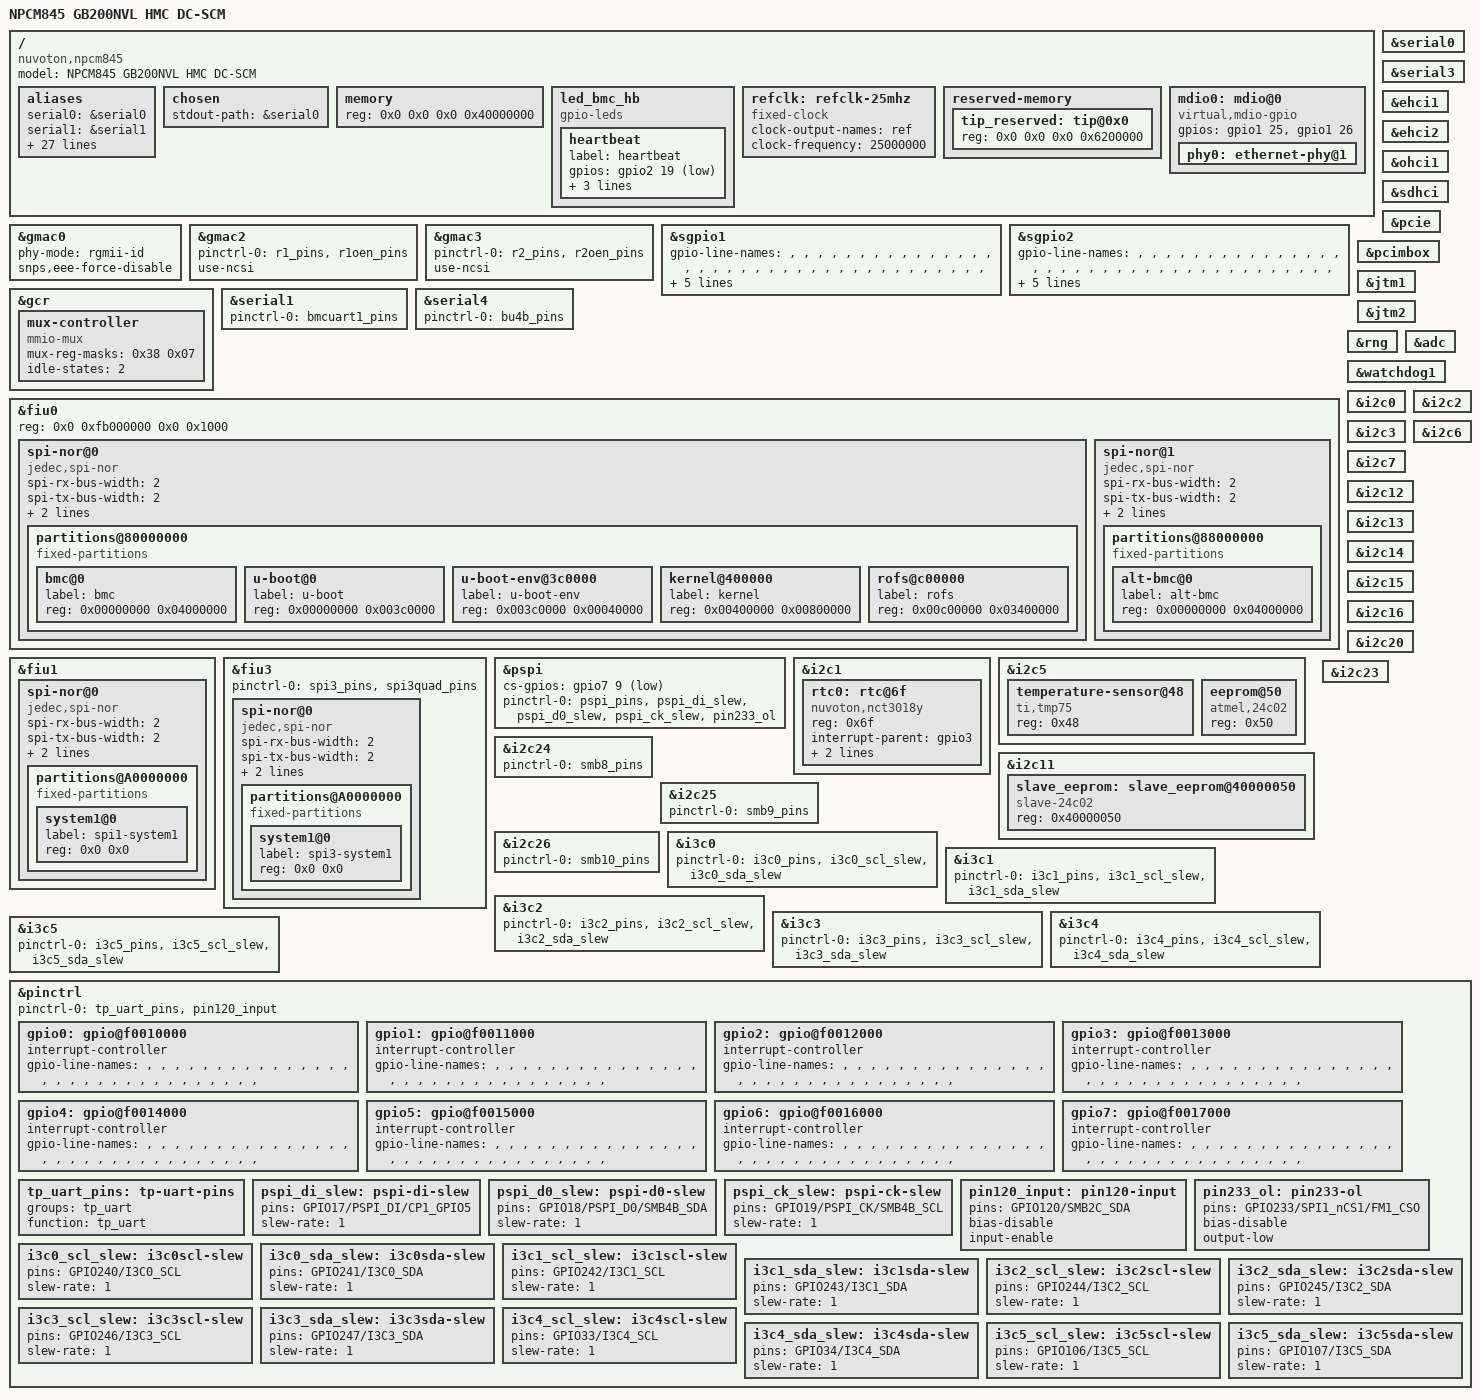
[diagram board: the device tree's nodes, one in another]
// SPDX-License-Identifier: GPL-2.0
// Copyright (c) 2025 Nuvoton Technology

/dts-v1/;
#include "nuvoton-npcm845.dtsi"
#include <dt-bindings/leds/common.h>

/ {
	model = "NPCM845 GB200NVL HMC DC-SCM";
	compatible = "nuvoton,npcm845";

	aliases {
		serial0 = &serial0;
		serial1 = &serial1;
		serial2 = &serial3;
		serial3 = &serial4;
		ethernet0 = &gmac0;
		ethernet2 = &gmac2;
		ethernet3 = &gmac3;
		mdio-gpio0 = &mdio0;
		fiu0 = &fiu0;
		fiu1 = &fiu1;
		fiu3 = &fiu3;
		i2c0 = &i2c0;
		i2c1 = &i2c1;
		i2c2 = &i2c2;
		i2c3 = &i2c3;
		i2c5 = &i2c5;
		i2c6 = &i2c6;
		i2c7 = &i2c7;
		i2c11 = &i2c11;
		i2c12 = &i2c12;
		i2c13 = &i2c13;
		i2c14 = &i2c14;
		i2c15 = &i2c15;
		i2c16 = &i2c16;
		i2c20 = &i2c20;
		i2c23 = &i2c23;
		i2c24 = &i2c24;
		i2c25 = &i2c25;
		i2c26 = &i2c26;
	};

	chosen {
		stdout-path = &serial0;
	};

	memory {
		reg = <0x0 0x0 0x0 0x40000000>;
	};

	led_bmc_hb {
		compatible = "gpio-leds";
		heartbeat {
			label = "heartbeat";
			gpios = <&gpio2 19 GPIO_ACTIVE_LOW>; /* gpio83 */
			linux,default-trigger = "timer";
			led-pattern = <1000 1000>;
			default-state = "on";
		};
	};

	refclk: refclk-25mhz {
		compatible = "fixed-clock";
		clock-output-names = "ref";
		clock-frequency = <25000000>;
		#clock-cells = <0>;
	};

	reserved-memory {
		#address-cells = <2>;
		#size-cells = <2>;
		ranges;

		tip_reserved: tip@0x0 {
			reg = <0x0 0x0 0x0 0x6200000>;
		};
	};

	mdio0: mdio@0 {
		compatible = "virtual,mdio-gpio";
		gpios = <&gpio1 25 GPIO_ACTIVE_HIGH>,
			<&gpio1 26 GPIO_ACTIVE_HIGH>; 
		#address-cells = <1>;
		#size-cells = <0>;

		phy0: ethernet-phy@1 {
		};
	};
};

&gmac0 {
	phy-mode = "rgmii-id";
	snps,eee-force-disable;
	status = "okay";
};

&gmac2 {
	//status = "okay";
	pinctrl-names = "default";
	pinctrl-0 = <&r1_pins
		     &r1oen_pins>;
	use-ncsi;
	//mellanox,multi-host;
};

&gmac3 {
	//status = "okay";
	pinctrl-names = "default";
	pinctrl-0 = <&r2_pins
		     &r2oen_pins>;
	use-ncsi;
	//mellanox,multi-host;
};

&sgpio1 {
	status = "okay";
	gpio-line-names =
		"","","","","","","","",
		"","","","","","","","",
		"","","","","","","","",
		"","","","","","","","",
		"","","","","","","","",
		"","","","","","","","",
		"","","","","","","","",
		"","","","","","","","",
		"","","","","","","","",
		"","","","","","","","",
		"","","","","","","","",
		"","","","","","","","",
		"","","","","","","","",
		"","","","","","","","",
		"","","","","","","","",
		"","","","","","","","";
};

&sgpio2 {
	status = "okay";
	gpio-line-names =
		"","","","","","","","",
		"","","","","","","","",
		"","","","","","","","",
		"","","","","","","","",
		"","","","","","","","",
		"","","","","","","","",
		"","","","","","","","",
		"","","","","","","","",
		"","","","","","","","",
		"","","","","","","","",
		"","","","","","","","",
		"","","","","","","","",
		"","","","","","","","",
		"","","","","","","","",
		"","","","","","","","",
		"","","","","","","","";
};

&gcr {
	mux-controller {
		compatible = "mmio-mux";
		#mux-control-cells = <1>;
		mux-reg-masks = <0x38 0x07>;
		idle-states = <2>; // UART switch mode 3
	};
};

&serial0 {
	status = "okay";
};

&serial1 {
	status = "okay";
	pinctrl-names = "default";
	pinctrl-0 = <&bmcuart1_pins>;
};

&serial3 {
	status = "okay";
};

&serial4 {
	status = "okay";
	pinctrl-names = "default";
	pinctrl-0 = <&bu4b_pins>;
};

&fiu0 {
	status = "okay";
	reg = <0x0 0xfb000000 0x0 0x1000>;
	reg-names = "control";
	spi-nor@0 {
		compatible = "jedec,spi-nor";
		#address-cells = <1>;
		#size-cells = <1>;
		spi-rx-bus-width = <2>;
		spi-tx-bus-width = <2>;
		reg = <0>;
		spi-max-frequency = <5000000>;
		partitions@80000000 {
			compatible = "fixed-partitions";
			#address-cells = <1>;
			#size-cells = <1>;
			bmc@0 {
				label = "bmc";
				reg = <0x00000000 0x04000000>;
			};
			u-boot@0 {
				label = "u-boot";
				reg = <0x00000000 0x003c0000>;
			};
			u-boot-env@3c0000 {
				label = "u-boot-env";
				reg = <0x003c0000 0x00040000>;
			};
			kernel@400000 {
				label = "kernel";
				reg = <0x00400000 0x00800000>;
			};
			rofs@c00000 {
				label = "rofs";
				reg = <0x00c00000 0x03400000>;
			};
		};
	};
	spi-nor@1 {
		compatible = "jedec,spi-nor";
		#address-cells = <1>;
		#size-cells = <1>;
		spi-rx-bus-width = <2>;
		spi-tx-bus-width = <2>;
		reg = <1>;
		spi-max-frequency = <5000000>;
		partitions@88000000 {
			compatible = "fixed-partitions";
			#address-cells = <1>;
			#size-cells = <1>;
			alt-bmc@0 {
				label = "alt-bmc";
				reg = <0x00000000 0x04000000>;
			};
		};
	};
};

&fiu1 {
	/*pinctrl-0 = <&spi1_pins>, <&spi1quad_pins>;*/
	status = "okay";
	spi-nor@0 {
		compatible = "jedec,spi-nor";
		#address-cells = <1>;
		#size-cells = <1>;
		spi-rx-bus-width = <2>;
		spi-tx-bus-width = <2>;
		reg = <0>;
		spi-max-frequency = <5000000>;
		partitions@A0000000 {
			compatible = "fixed-partitions";
			#address-cells = <1>;
			#size-cells = <1>;
			system1@0 {
				label = "spi1-system1";
				reg = <0x0 0x0>;
			};
		};
	};
};

&fiu3 {
	pinctrl-0 = <&spi3_pins>, <&spi3quad_pins>;
	status = "okay";
	spi-nor@0 {
		compatible = "jedec,spi-nor";
		#address-cells = <1>;
		#size-cells = <1>;
		spi-rx-bus-width = <2>;
		spi-tx-bus-width = <2>;
		reg = <0>;
		spi-max-frequency = <5000000>;
		partitions@A0000000 {
			compatible = "fixed-partitions";
			#address-cells = <1>;
			#size-cells = <1>;
			system1@0 {
				label = "spi3-system1";
				reg = <0x0 0x0>;
			};
		};
	};
};

&ehci1 {
	status = "okay";
};

&ehci2 {
	status = "okay";
};

&ohci1 {
        status = "okay";
};

&sdhci {
	status = "okay";
};

&pcie {
	/* used for e1000e PCI -> AXI window opening */
	//dma-ranges = <0x02000000 0 0x00000000 0x0 0x00000000 0 0x40000000>;
	//npcm-pci-ep-rst = <&gpio3 24 1>;
	status = "okay";
};

&pcimbox {
	status = "okay";
};

&jtm1 {
	status = "okay";
};

&jtm2 {
	status = "okay";
};

&rng {
	status = "okay";
};

&adc {
	#io-channel-cells = <1>;
	status = "okay";
};

&watchdog1 {
	status = "okay";
};


&pspi {
	status = "okay";
	cs-gpios = <&gpio7 9 GPIO_ACTIVE_LOW>; /* gpio233 */
	pinctrl-0 = <&pspi_pins
		     &pspi_di_slew
		     &pspi_d0_slew
		     &pspi_ck_slew
		     &pin233_ol>;

	// NPCT760AACYX TPM
};

&i2c0 {
	status = "okay";
};

&i2c1 {
	status = "okay";
	rtc0: rtc@6f {
		compatible = "nuvoton,nct3018y";
		reg = <0x6f>;
		interrupt-parent = <&gpio3>;
		interrupts = <24 IRQ_TYPE_EDGE_FALLING>; /* gpio120 */
		interrupt-names = "irq";
		wakeup-source;
	};
};

&i2c2 {
	status = "okay";
};

&i2c3 {
	status = "okay";
};

&i2c5 {
	status = "okay";
	temperature-sensor@48 {
		compatible = "ti,tmp75";
		reg = <0x48>;
	};

	eeprom@50 {
		compatible = "atmel,24c02";
		reg = <0x50>;
	};
};

&i2c6 {
	status = "okay";
};

&i2c7 {
	status = "okay";
};

&i2c11 {
	status = "okay";
	//Internal eeprom for DVO
	slave_eeprom: slave_eeprom@40000050 {
		compatible = "slave-24c02";
		reg = <0x40000050>;
		status = "okay";
	};
};

&i2c12 {
	status = "okay";
};

&i2c13 {
	status = "okay";
};

&i2c14 {
	status = "okay";
};

&i2c15 {
	status = "okay";
};

&i2c16 {
	status = "okay";
};

&i2c20 {
	status = "okay";
};

&i2c23 {
	status = "okay";
};

&i2c24 {
	status = "okay";
	pinctrl-0 = <&smb8_pins>;
};

&i2c25 {
	status = "okay";
	pinctrl-0 = <&smb9_pins>;
};

&i2c26 {
	status = "okay";
	pinctrl-0 = <&smb10_pins>;
};

&i3c0 {
	status = "okay";
	pinctrl-names = "default";
	pinctrl-0 = <&i3c0_pins
		     &i3c0_scl_slew
		     &i3c0_sda_slew>;
};

&i3c1 {
	status = "okay";
	pinctrl-names = "default";
	pinctrl-0 = <&i3c1_pins
		     &i3c1_scl_slew
		     &i3c1_sda_slew>;
};

&i3c2 {
	status = "okay";
	pinctrl-names = "default";
	pinctrl-0 = <&i3c2_pins
		     &i3c2_scl_slew
		     &i3c2_sda_slew>;
};

&i3c3 {
	status = "okay";
	pinctrl-names = "default";
	pinctrl-0 = <&i3c3_pins
		     &i3c3_scl_slew
		     &i3c3_sda_slew>;
};

&i3c4 {
	status = "okay";
	pinctrl-names = "default";
	pinctrl-0 = <&i3c4_pins
		     &i3c4_scl_slew
		     &i3c4_sda_slew>;
};

&i3c5 {
	status = "okay";
	pinctrl-names = "default";
	pinctrl-0 = <&i3c5_pins
		     &i3c5_scl_slew
		     &i3c5_sda_slew>;
};

&pinctrl {
	pinctrl-names = "default";
	pinctrl-0 = <&tp_uart_pins
		     &pin120_input>;

	gpio0: gpio@f0010000 {
		interrupt-controller;
		#interrupt-cells = <2>;
		gpio-line-names =
		/*0-31*/
		"","","","","","","","",
		"","","","","","","","",
		"","","","","","","","",
		"","","","","","","","";
	};

	gpio1: gpio@f0011000 {
		interrupt-controller;
		#interrupt-cells = <2>;
		gpio-line-names =
		/*32-63*/
		"","","","","","","","",
		"","","","","","","","",
		"","","","","","","","",
		"","","","","","","","";
	};

	gpio2: gpio@f0012000 {
		interrupt-controller;
		#interrupt-cells = <2>;
		gpio-line-names =
		/*64-95*/
		"","","","","","","","",
		"","","","","","","","",
		"","","","","","","","",
		"","","","","","","","";
	};

	gpio3: gpio@f0013000 {
		interrupt-controller;
		#interrupt-cells = <2>; gpio-line-names =
		/*96-127*/
		"","","","","","","","",
		"","","","","","","","",
		"","","","","","","","",
		"","","","","","","","";
	};

	gpio4: gpio@f0014000 {
		interrupt-controller;
		#interrupt-cells = <2>;
		gpio-line-names =
		/*128-159*/
		"","","","","","","","",
		"","","","","","","","",
		"","","","","","","","",
		"","","","","","","","";
	};

	gpio5: gpio@f0015000 {
		interrupt-controller;
		#interrupt-cells = <2>;
		gpio-line-names =
		/*160-191*/
		"","","","","","","","",
		"","","","","","","","",
		"","","","","","","","",
		"","","","","","","","";
	};

	gpio6: gpio@f0016000 {
		interrupt-controller;
		#interrupt-cells = <2>;
		gpio-line-names =
		/*192-223*/
		"","","","","","","","",
		"","","","","","","","",
		"","","","","","","","",
		"","","","","","","",""; };

	gpio7: gpio@f0017000 {
		interrupt-controller;
		#interrupt-cells = <2>;
		gpio-line-names =
		/*224-255*/
		"","","","","","","","",
		"","","","","","","","",
		"","","","","","","","",
		"","","","","","","","";
	};

	tp_uart_pins: tp-uart-pins {
		groups = "tp_uart";
		function = "tp_uart";
	};

	pspi_di_slew: pspi-di-slew {
		pins = "GPIO17/PSPI_DI/CP1_GPIO5";
		slew-rate = <1>;
	};

	pspi_d0_slew: pspi-d0-slew {
		pins = "GPIO18/PSPI_D0/SMB4B_SDA";
		slew-rate = <1>;
	};

	pspi_ck_slew: pspi-ck-slew {
		pins = "GPIO19/PSPI_CK/SMB4B_SCL";
		slew-rate = <1>;
	};

	pin120_input: pin120-input {
		pins = "GPIO120/SMB2C_SDA";
		bias-disable;
		input-enable;
	};

	pin233_ol: pin233-ol {
		pins = "GPIO233/SPI1_nCS1/FM1_CSO";
		bias-disable;
		output-low;
	};

	i3c0_scl_slew: i3c0scl-slew {
		pins = "GPIO240/I3C0_SCL";
		slew-rate = <1>;
	};

	i3c0_sda_slew: i3c0sda-slew {
		pins = "GPIO241/I3C0_SDA";
		slew-rate = <1>;
	};

	i3c1_scl_slew: i3c1scl-slew {
		pins = "GPIO242/I3C1_SCL";
		slew-rate = <1>;
	};

	i3c1_sda_slew: i3c1sda-slew {
		pins = "GPIO243/I3C1_SDA";
		slew-rate = <1>;
	};

	i3c2_scl_slew: i3c2scl-slew {
		pins = "GPIO244/I3C2_SCL";
		slew-rate = <1>;
	};

	i3c2_sda_slew: i3c2sda-slew {
		pins = "GPIO245/I3C2_SDA";
		slew-rate = <1>;
	};

	i3c3_scl_slew: i3c3scl-slew {
		pins = "GPIO246/I3C3_SCL";
		slew-rate = <1>;
	};

	i3c3_sda_slew: i3c3sda-slew {
		pins = "GPIO247/I3C3_SDA";
		slew-rate = <1>;
	};

	i3c4_scl_slew: i3c4scl-slew {
		pins = "GPIO33/I3C4_SCL";
		slew-rate = <1>;
	};

	i3c4_sda_slew: i3c4sda-slew {
		pins = "GPIO34/I3C4_SDA";
		slew-rate = <1>;
	};

	i3c5_scl_slew: i3c5scl-slew {
		pins = "GPIO106/I3C5_SCL";
		slew-rate = <1>;
	};

	i3c5_sda_slew: i3c5sda-slew {
		pins = "GPIO107/I3C5_SDA";
		slew-rate = <1>;
	};
};
